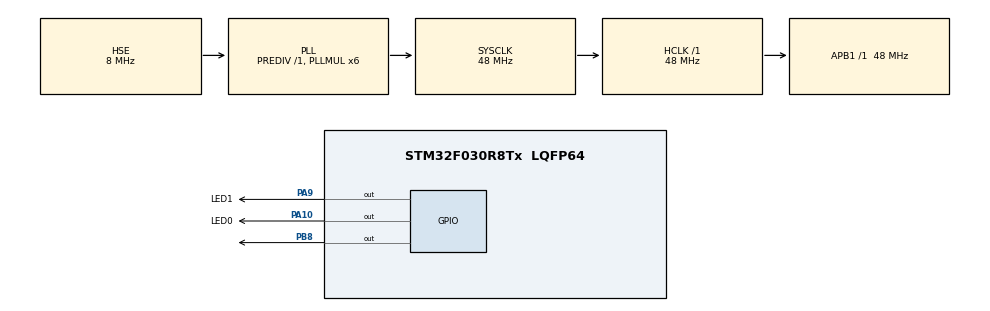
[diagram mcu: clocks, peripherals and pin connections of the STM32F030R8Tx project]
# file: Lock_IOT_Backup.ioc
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Mcu.Family=STM32F0
Mcu.Name=STM32F030R8Tx
Mcu.Package=LQFP64
PA10.GPIO_Label=LED0
PA10.GPIO_PuPd=GPIO_NOPULL
PA10.GPIO_Speed=GPIO_SPEED_FREQ_HIGH
PA10.PinState=GPIO_PIN_SET
PA10.Signal=GPIO_Output
PA13.Mode=Serial_Wire
PA13.Signal=SYS_SWDIO
PA14.Mode=Serial_Wire
PA14.Signal=SYS_SWCLK
PA9.GPIO_Label=LED1
PA9.GPIO_PuPd=GPIO_NOPULL
PA9.GPIO_Speed=GPIO_SPEED_FREQ_HIGH
PA9.PinState=GPIO_PIN_SET
PA9.Signal=GPIO_Output
PB8.GPIO_FM8=__NULL
PB8.GPIO_Speed=GPIO_SPEED_FREQ_HIGH
PB8.PinState=GPIO_PIN_SET
PB8.Signal=GPIO_Output
PF0-OSC_IN.Mode=HSE-External-Oscillator
PF0-OSC_IN.Signal=RCC_OSC_IN
PF1-OSC_OUT.Mode=HSE-External-Oscillator
PF1-OSC_OUT.Signal=RCC_OSC_OUT
ProjectManager.HeapSize=0x200
ProjectManager.StackSize=0x400
ProjectManager.TargetToolchain=MDK-ARM V5
RCC.AHBFreq_Value=48000000
RCC.APB1Freq_Value=48000000
RCC.APB1TimFreq_Value=48000000
RCC.HCLKFreq_Value=48000000
RCC.PLLMUL=RCC_PLL_MUL6
RCC.PLLSourceVirtual=RCC_PLLSOURCE_HSE
RCC.SYSCLKFreq_VALUE=48000000
RCC.SYSCLKSource=RCC_SYSCLKSOURCE_PLLCLK
RCC.Usart1ClockSelection=RCC_USART1CLKSOURCE_SYSCLK
board=custom

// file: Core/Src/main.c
/* USER CODE BEGIN Header */
/**
  ******************************************************************************
  * @file           : main.c
  * @brief          : Main program body
  ******************************************************************************
  * @attention
  *
  * <h2><center>&copy; Copyright (c) 2019 STMicroelectronics.
  * All rights reserved.</center></h2>
  *
  * This software component is licensed by ST under BSD 3-Clause license,
  * the "License"; You may not use this file except in compliance with the
  * License. You may obtain a copy of the License at:
  *                        opensource.org/licenses/BSD-3-Clause
  *
  ******************************************************************************
  */
/* USER CODE END Header */

#include "main.h"
#include "gpio.h"

void SystemClock_Config(void);

int main(void)
{

  /* MCU Configuration--------------------------------------------------------*/

  /* Reset of all peripherals, Initializes the Flash interface and the Systick. */
  HAL_Init();

  /* Configure the system clock */
  SystemClock_Config();

  /* Initialize all configured peripherals */
  MX_GPIO_Init();
  /* USER CODE BEGIN 2 */
  HAL_GPIO_WritePin(GPIOB, GPIO_PIN_8, GPIO_PIN_RESET);
//		HAL_GPIO_WritePin(EX_VDD_CON_GPIO_Port,EX_VDD_CON_Pin,GPIO_PIN_SET);

  /* USER CODE END 2 */

  /* Infinite loop */
  while (1)
  {

    /* USER CODE BEGIN 3 */
			 HAL_GPIO_TogglePin(LED0_GPIO_Port,LED0_Pin);
			 HAL_Delay(100);
  }
  /* USER CODE END 3 */
}

void SystemClock_Config(void)
{
  RCC_OscInitTypeDef RCC_OscInitStruct = {0};
  RCC_ClkInitTypeDef RCC_ClkInitStruct = {0};

  /** Initializes the CPU, AHB and APB busses clocks
  */
  RCC_OscInitStruct.OscillatorType = RCC_OSCILLATORTYPE_HSE;
  RCC_OscInitStruct.HSEState = RCC_HSE_ON;
  RCC_OscInitStruct.PLL.PLLState = RCC_PLL_ON;
  RCC_OscInitStruct.PLL.PLLSource = RCC_PLLSOURCE_HSE;
  RCC_OscInitStruct.PLL.PLLMUL = RCC_PLL_MUL6;
  RCC_OscInitStruct.PLL.PREDIV = RCC_PREDIV_DIV1;
  if (HAL_RCC_OscConfig(&RCC_OscInitStruct) != HAL_OK)
  {
    Error_Handler();
  }
  /** Initializes the CPU, AHB and APB busses clocks
  */
  RCC_ClkInitStruct.ClockType = RCC_CLOCKTYPE_HCLK|RCC_CLOCKTYPE_SYSCLK
                              |RCC_CLOCKTYPE_PCLK1;
  RCC_ClkInitStruct.SYSCLKSource = RCC_SYSCLKSOURCE_PLLCLK;
  RCC_ClkInitStruct.AHBCLKDivider = RCC_SYSCLK_DIV1;
  RCC_ClkInitStruct.APB1CLKDivider = RCC_HCLK_DIV1;

  if (HAL_RCC_ClockConfig(&RCC_ClkInitStruct, FLASH_LATENCY_1) != HAL_OK)
  {
    Error_Handler();
  }
}

void Error_Handler(void)
{
}

/************************ (C) COPYRIGHT STMicroelectronics *****END OF FILE****/
